VERSION ""

NS_ :

BS_:

BU_: XXX

BO_ 0 US: 32 XXX
 SG_ CHECKSUM : 0|16@1+ (1,0) [0|65535] "" XXX
 SG_ COUNTER : 16|8@1+ (1,0) [0|255] "" XXX
 SG_ ESP_DISABLED : 42|3@1+ (1,0) [0|63] "" XXX

BO_ 53 ACCELERATOR: 32 XXX
 SG_ CHECKSUM : 0|16@1+ (1,0) [0|65535] "" XXX
 SG_ COUNTER : 16|8@1+ (1,0) [0|255] "" XXX
 SG_ GEAR : 192|3@1+ (1,0) [0|7] "" XXX
 SG_ ACCELERATOR_PEDAL : 40|8@1+ (1,0) [0|255] "" XXX

BO_ 80 LKAS: 16 XXX
 SG_ STEER_REQ_3 : 67|1@1+ (1,0) [0|7] "" XXX
 SG_ STEER_REQ_2 : 65|1@1+ (1,0) [0|1] "" XXX
 SG_ NEW_SIGNAL_5 : 62|1@1+ (1,0) [0|1] "" XXX
 SG_ STEER_REQ : 52|1@1+ (1,0) [0|1] "" XXX
 SG_ TORQUE_REQUEST : 41|11@1+ (1,-1024) [0|4095] "" XXX
 SG_ LDW_STATUS : 38|2@1+ (1,0) [0|255] "" XXX
 SG_ NEW_SIGNAL_4 : 32|1@1+ (1,0) [0|1] "" XXX
 SG_ NEW_SIGNAL_1 : 26|3@1+ (1,0) [0|255] "" XXX
 SG_ COUNTER : 16|8@1+ (1,0) [0|255] "" XXX
 SG_ CHECKSUM : 0|16@1+ (1,0) [0|65535] "" XXX

BO_ 96 ESP_STATUS: 32 XXX
 SG_ CHECKSUM : 0|16@1+ (1,0) [0|65535] "" XXX
 SG_ COUNTER : 16|8@1+ (1,0) [0|255] "" XXX
 SG_ ESP_DISABLED : 42|3@1+ (1,0) [0|63] "" XXX

BO_ 101 BRAKE: 32 XXX
 SG_ CHECKSUM : 0|16@1+ (1,0) [0|65535] "" XXX
 SG_ COUNTER : 16|8@1+ (1,0) [0|255] "" XXX
 SG_ BRAKE_PRESSED : 57|1@1+ (1,0) [0|3] "" XXX

BO_ 160 WHEEL_SPEEDS: 24 XXX
 SG_ CHECKSUM : 0|16@1+ (1,0) [0|65535] "" XXX
 SG_ COUNTER : 16|8@1+ (1,0) [0|255] "" XXX
 SG_ WHEEL_SPEED_1 : 64|16@1+ (0.03125,0) [0|65535] "m/s" XXX
 SG_ WHEEL_SPEED_2 : 80|16@1+ (0.03125,0) [0|65535] "m/s" XXX
 SG_ WHEEL_SPEED_3 : 96|16@1+ (0.03125,0) [0|65535] "m/s" XXX
 SG_ WHEEL_SPEED_4 : 112|16@1+ (0.03125,0) [0|65535] "m/s" XXX

BO_ 234 STEERING_SENSORS_ALT: 24 XXX
 SG_ CHECKSUM : 0|16@1+ (1,0) [0|65535] "" XXX
 SG_ COUNTER : 16|8@1+ (1,0) [0|255] "" XXX
 SG_ STEERING_ANGLE : 96|16@1- (-0.1,0) [0|255] "deg" XXX
 SG_ STEERING_ANGLE_2 : 128|16@1- (-0.1,0) [0|65535] "deg" XXX
 SG_ STEERING_TORQUE : 80|12@1- (1,0) [0|65535] "" XXX

BO_ 293 STEERING_SENSORS: 16 XXX
 SG_ CHECKSUM : 0|16@1+ (1,0) [0|65535] "" XXX
 SG_ COUNTER : 16|8@1+ (1,0) [0|255] "" XXX
 SG_ STEERING_RATE : 40|8@1- (-0.1,0) [0|255] "deg/s" XXX
 SG_ STEERING_ANGLE : 24|16@1- (-0.1,0) [0|255] "deg" XXX

BO_ 373 SCC1: 24 XXX
 SG_ CHECKSUM : 0|16@1+ (1,0) [0|65535] "" XXX
 SG_ COUNTER : 16|8@1+ (1,0) [0|255] "" XXX
 SG_ ACCEL_REQ : 48|13@1- (1,0) [0|1023] "" XXX
 SG_ CRUISE_ACTIVE : 68|1@0+ (1,0) [0|1] "" XXX

BO_ 416 CRUISE_INFO: 32 XXX
 SG_ CHECKSUM : 0|16@1+ (1,0) [0|65535] "" XXX
 SG_ COUNTER : 16|8@1+ (1,0) [0|255] "" XXX
 SG_ SET_SPEED : 102|7@0+ (1,0) [0|127] "km/h or mph" XXX
 SG_ CRUISE_ACTIVE : 184|1@1+ (1,0) [0|1] "" XXX

BO_ 463 CRUISE_BUTTONS: 8 XXX
 SG_ CHECKSUM : 0|16@1+ (1,0) [0|65535] "" XXX
 SG_ COUNTER : 16|8@1+ (1,0) [0|255] "" XXX
 SG_ LKAS_BTN : 23|1@1+ (1,0) [0|1] "" XXX
 SG_ PAUSE_RESUME_BTN : 18|1@1+ (1,0) [0|1] "" XXX
 SG_ DISTANCE_BTN : 16|2@1+ (1,0) [0|3] "" XXX
 SG_ NORMAL_CRUISE_BTN : 21|1@1+ (1,0) [0|1] "" XXX
 SG_ ADAPTIVE_CRUISE_BTN : 19|1@1+ (1,0) [0|1] "" XXX

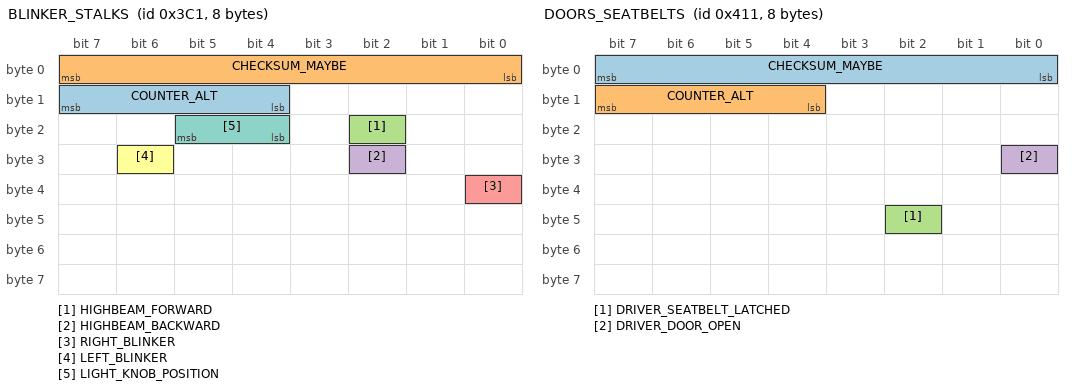
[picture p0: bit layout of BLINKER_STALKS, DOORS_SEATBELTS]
BO_ 961 BLINKER_STALKS: 8 XXX
 SG_ COUNTER_ALT : 15|4@0+ (1,0) [0|15] "" XXX
 SG_ CHECKSUM_MAYBE : 7|8@0+ (1,0) [0|255] "" XXX
 SG_ HIGHBEAM_FORWARD : 18|1@0+ (1,0) [0|1] "" XXX
 SG_ HIGHBEAM_BACKWARD : 26|1@0+ (1,0) [0|1] "" XXX
 SG_ RIGHT_BLINKER : 32|1@0+ (1,0) [0|1] "" XXX
 SG_ LEFT_BLINKER : 30|1@0+ (1,0) [0|1] "" XXX
 SG_ LIGHT_KNOB_POSITION : 21|2@0+ (1,0) [0|3] "" XXX

BO_ 1041 DOORS_SEATBELTS: 8 XXX
 SG_ CHECKSUM_MAYBE : 7|8@0+ (1,0) [0|65535] "" XXX
 SG_ COUNTER_ALT : 15|4@0+ (1,0) [0|15] "" XXX
 SG_ DRIVER_SEATBELT_LATCHED : 42|1@0+ (1,0) [0|1] "" XXX
 SG_ DRIVER_DOOR_OPEN : 24|1@1+ (1,0) [0|1] "" XXX

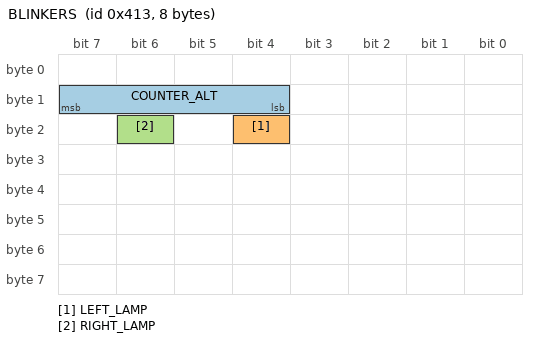
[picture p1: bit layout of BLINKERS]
BO_ 1043 BLINKERS: 8 XXX
 SG_ COUNTER_ALT : 15|4@0+ (1,0) [0|15] "" XXX
 SG_ LEFT_LAMP : 20|1@0+ (1,0) [0|1] "" XXX
 SG_ RIGHT_LAMP : 22|1@0+ (1,0) [0|1] "" XXX

BO_ 1240 CLUSTER_INFO: 8 XXX
 SG_ DISTANCE_UNIT : 0|1@1+ (1,0) [0|1] "" XXX

BO_ 48 NEW_MSG_1: 24 XXX

BO_ 181 GAS_PRESS: 32 XXX
 SG_ CHECKSUM : 0|16@1+ (1,0) [0|65535] "" XXX
 SG_ COUNTER : 16|8@1+ (1,0) [0|255] "" XXX
 SG_ ACCEL_PRESS_1 : 80|16@1+ (0.03125,0) [0|65535] "m/s" XXX
 SG_ ACCEL_PRESS_0 : 64|16@1+ (0.03125,0) [0|65535] "m/s" XXX
 SG_ ACCEL_COUNTER : 55|8@0+ (1,0) [0|255] "" XXX
 SG_ ACCEL_PRESS_2 : 31|8@0+ (1,0) [0|255] "" XXX
 SG_ ACCEL_PRESS : 200|8@1+ (1,0) [0|255] "" XXX

BO_ 480 ADAS_STATUS: 16 XXX
 SG_ ADAS_undef01 : 24|8@1+ (1,0) [0|255] "" XXX
 SG_ ADAS_COLOR : 47|2@1+ (1,0) [0|1] "" XXX
 SG_ CHECKSUM : 0|16@1+ (1,0) [0|65535] "" XXX
 SG_ COUNTER : 16|8@1+ (1,0) [0|255] "" XXX

BO_ 298 LKAS_KA4: 16 XXX
 SG_ STEER_REQ : 52|1@1+ (1,0) [0|1] "" XXX
 SG_ TORQUE_REQUEST : 41|11@1+ (1,-1024) [0|4095] "" XXX
 SG_ COUNTER : 16|8@1+ (1,0) [0|255] "" XXX
 SG_ CHECKSUM : 0|16@1+ (1,0) [0|65535] "" XXX
 SG_ LKAS_undef03 : 80|1@0+ (1,0) [0|1] "" XXX
 SG_ LKAS_undef04 : 109|3@1+ (1,0) [0|7] "" XXX
 SG_ LKAS_undef05 : 104|5@1+ (1,0) [0|31] "" XXX
 SG_ LDWS_STATUS : 38|3@1+ (1,0) [0|65535] "" XXX
 SG_ LKAS_LDWD01 : 24|3@1+ (1,0) [0|7] "" XXX
 SG_ LKAS_LDWS02 : 63|4@0+ (1,0) [0|15] "" XXX
 SG_ LKAS_undef01 : 28|2@0+ (1,0) [0|3] "" XXX

BO_ 256 BRAKE_D: 32 XXX
 SG_ COUNTER : 16|8@1+ (1,0) [0|255] "" XXX
 SG_ CHECKSUM : 0|16@1+ (1,0) [0|65535] "" XXX
 SG_ DRIVER_BRAKE : 32|1@0+ (1,0) [0|1] "" XXX

BO_ 64 GEARKA4: 32 XXX
 SG_ SHIFTER : 32|3@1+ (1,0) [0|15] "" XXX

CM_ SG_ 961 COUNTER_ALT "only increments on change";
CM_ SG_ 1041 COUNTER_ALT "only increments on change";
CM_ SG_ 1043 COUNTER_ALT "only increments on change";
CM_ SG_ 298 LDWS_STATUS "0:off 1:on 2: 4:";
CM_ SG_ 298 LKAS_LDWD01 "2: 6: 7:";
CM_ SG_ 480 ADAS_COLOR "0:OFF 1:WHITE 2:GREEN 3:BLINK";
CM_ SG_ 64 SHIFTER "0:P 5:D 7:R 6:N";
VAL_ 64 SHIFTER 0 "P" 5 "D" 6 "N" 7 "R" ;
VAL_ 53 GEAR 0 "P" 5 "D" 6 "N" 7 "R" ;
